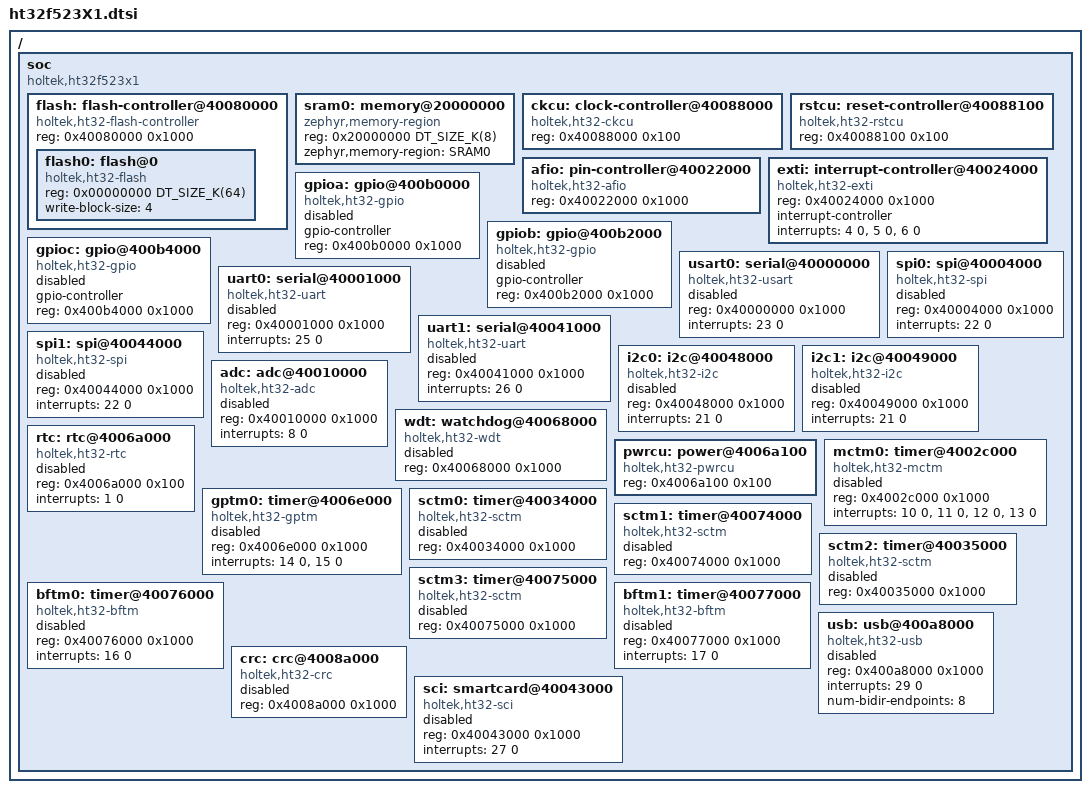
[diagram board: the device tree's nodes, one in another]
/*
 * Copyright (c) 2025 Alex Fabre <alex.fabre@rtone.fr>
 *
 * SPDX-License-Identifier: Apache-2.0
 */

#include <holtek/ht32/f5/ht32f523.dtsi>
#include <mem.h>

/ {
	soc {
		compatible = "holtek,ht32f523x1", "holtek,ht32f523", "simple-bus";

		flash: flash-controller@40080000 {
			compatible = "holtek,ht32-flash-controller";
			reg = <0x40080000 0x1000>;
			#address-cells = <1>;
			#size-cells = <1>;

			flash0: flash@0 {
				compatible = "holtek,ht32-flash", "soc-nv-flash";
				reg = <0x00000000 DT_SIZE_K(64)>;
				write-block-size = <4>;
			};
		};

		sram0: memory@20000000 {
			compatible = "zephyr,memory-region", "mmio-sram";
			reg = <0x20000000 DT_SIZE_K(8)>;
			zephyr,memory-region = "SRAM0";
		};

		ckcu: clock-controller@40088000 {
			compatible = "holtek,ht32-ckcu";
			reg = <0x40088000 0x100>;
			#clock-cells = <1>;
		};

		rstcu: reset-controller@40088100 {
			compatible = "holtek,ht32-rstcu";
			reg = <0x40088100 0x100>;
			#reset-cells = <1>;
		};

		afio: pin-controller@40022000 {
			compatible = "holtek,ht32-afio";
			reg = <0x40022000 0x1000>;
		};

		exti: interrupt-controller@40024000 {
			compatible = "holtek,ht32-exti";
			reg = <0x40024000 0x1000>;
			interrupt-controller;
			#interrupt-cells = <1>;
			interrupts = <4 0>, <5 0>, <6 0>;
			interrupt-names = "exti0-1", "exti2-3", "exti4-15";
		};

		gpioa: gpio@400b0000 {
			compatible = "holtek,ht32-gpio";
			gpio-controller;
			#gpio-cells = <2>;
			reg = <0x400b0000 0x1000>;
			status = "disabled";
		};

		gpiob: gpio@400b2000 {
			compatible = "holtek,ht32-gpio";
			gpio-controller;
			#gpio-cells = <2>;
			reg = <0x400b2000 0x1000>;
			status = "disabled";
		};

		gpioc: gpio@400b4000 {
			compatible = "holtek,ht32-gpio";
			gpio-controller;
			#gpio-cells = <2>;
			reg = <0x400b4000 0x1000>;
			status = "disabled";
		};

		usart0: serial@40000000 {
			compatible = "holtek,ht32-usart";
			reg = <0x40000000 0x1000>;
			interrupts = <23 0>;
			status = "disabled";
		};

		uart0: serial@40001000 {
			compatible = "holtek,ht32-uart";
			reg = <0x40001000 0x1000>;
			interrupts = <25 0>;
			status = "disabled";
		};

		uart1: serial@40041000 {
			compatible = "holtek,ht32-uart";
			reg = <0x40041000 0x1000>;
			interrupts = <26 0>;
			status = "disabled";
		};

		spi0: spi@40004000 {
			compatible = "holtek,ht32-spi";
			reg = <0x40004000 0x1000>;
			interrupts = <22 0>;
			#address-cells = <1>;
			#size-cells = <0>;
			status = "disabled";
		};

		spi1: spi@40044000 {
			compatible = "holtek,ht32-spi";
			reg = <0x40044000 0x1000>;
			interrupts = <22 0>;
			#address-cells = <1>;
			#size-cells = <0>;
			status = "disabled";
		};

		i2c0: i2c@40048000 {
			compatible = "holtek,ht32-i2c";
			reg = <0x40048000 0x1000>;
			interrupts = <21 0>;
			#address-cells = <1>;
			#size-cells = <0>;
			status = "disabled";
		};

		i2c1: i2c@40049000 {
			compatible = "holtek,ht32-i2c";
			reg = <0x40049000 0x1000>;
			interrupts = <21 0>;
			#address-cells = <1>;
			#size-cells = <0>;
			status = "disabled";
		};

		adc: adc@40010000 {
			compatible = "holtek,ht32-adc";
			reg = <0x40010000 0x1000>;
			interrupts = <8 0>;
			#io-channel-cells = <1>;
			status = "disabled";
		};

		wdt: watchdog@40068000 {
			compatible = "holtek,ht32-wdt";
			reg = <0x40068000 0x1000>;
			status = "disabled";
		};

		rtc: rtc@4006a000 {
			compatible = "holtek,ht32-rtc";
			reg = <0x4006a000 0x100>;
			interrupts = <1 0>;
			status = "disabled";
		};

		pwrcu: power@4006a100 {
			compatible = "holtek,ht32-pwrcu";
			reg = <0x4006a100 0x100>;
		};

		mctm0: timer@4002c000 {
			compatible = "holtek,ht32-mctm";
			reg = <0x4002c000 0x1000>;
			interrupts = <10 0>, <11 0>, <12 0>, <13 0>;
			interrupt-names = "brk", "up", "trig", "cc";
			status = "disabled";
		};

		gptm0: timer@4006e000 {
			compatible = "holtek,ht32-gptm";
			reg = <0x4006e000 0x1000>;
			interrupts = <14 0>, <15 0>;
			interrupt-names = "global", "vclk";
			status = "disabled";
		};

		sctm0: timer@40034000 {
			compatible = "holtek,ht32-sctm";
			reg = <0x40034000 0x1000>;
			status = "disabled";
		};

		sctm1: timer@40074000 {
			compatible = "holtek,ht32-sctm";
			reg = <0x40074000 0x1000>;
			status = "disabled";
		};

		sctm2: timer@40035000 {
			compatible = "holtek,ht32-sctm";
			reg = <0x40035000 0x1000>;
			status = "disabled";
		};

		sctm3: timer@40075000 {
			compatible = "holtek,ht32-sctm";
			reg = <0x40075000 0x1000>;
			status = "disabled";
		};

		bftm0: timer@40076000 {
			compatible = "holtek,ht32-bftm";
			reg = <0x40076000 0x1000>;
			interrupts = <16 0>;
			status = "disabled";
		};

		bftm1: timer@40077000 {
			compatible = "holtek,ht32-bftm";
			reg = <0x40077000 0x1000>;
			interrupts = <17 0>;
			status = "disabled";
		};

		usb: usb@400a8000 {
			compatible = "holtek,ht32-usb";
			reg = <0x400a8000 0x1000>;
			interrupts = <29 0>;
			num-bidir-endpoints = <8>;
			status = "disabled";
		};

		crc: crc@4008a000 {
			compatible = "holtek,ht32-crc";
			reg = <0x4008a000 0x1000>;
			status = "disabled";
		};

		sci: smartcard@40043000 {
			compatible = "holtek,ht32-sci";
			reg = <0x40043000 0x1000>;
			interrupts = <27 0>;
			status = "disabled";
		};
	};
};
